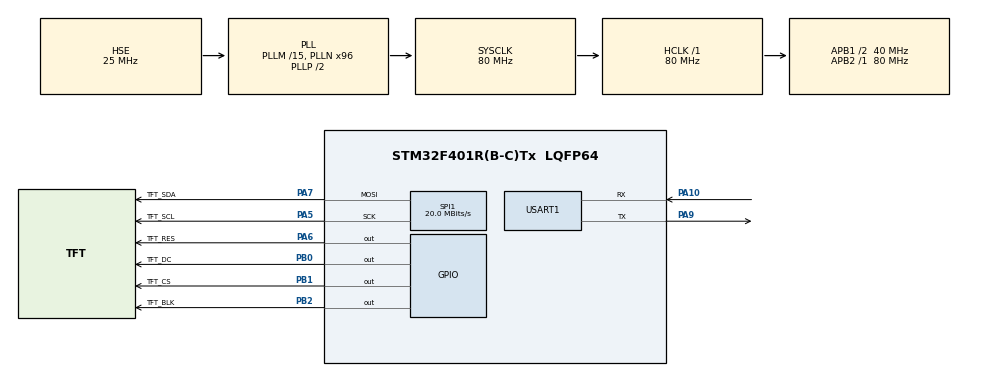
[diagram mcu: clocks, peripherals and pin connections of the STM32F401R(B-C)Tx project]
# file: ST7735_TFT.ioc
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Mcu.Family=STM32F4
Mcu.Name=STM32F401R(B-C)Tx
Mcu.Package=LQFP64
NVIC.PriorityGroup=NVIC_PRIORITYGROUP_4
PA10.Mode=Asynchronous
PA10.Signal=USART1_RX
PA13.Mode=Serial_Wire
PA13.Signal=SYS_JTMS-SWDIO
PA14.Mode=Serial_Wire
PA14.Signal=SYS_JTCK-SWCLK
PA5.GPIO_Label=TFT_SCL
PA5.Mode=TX_Only_Simplex_Unidirect_Master
PA5.Signal=SPI1_SCK
PA6.GPIO_Label=TFT_RES
PA6.Signal=GPIO_Output
PA7.GPIO_Label=TFT_SDA
PA7.Mode=TX_Only_Simplex_Unidirect_Master
PA7.Signal=SPI1_MOSI
PA9.Mode=Asynchronous
PA9.Signal=USART1_TX
PB0.GPIO_Label=TFT_DC
PB0.Signal=GPIO_Output
PB1.GPIO_Label=TFT_CS
PB1.Signal=GPIO_Output
PB2.GPIO_Label=TFT_BLK
PB2.Signal=GPIO_Output
PH0\ -\ OSC_IN.Mode=HSE-External-Oscillator
PH0\ -\ OSC_IN.Signal=RCC_OSC_IN
PH1\ -\ OSC_OUT.Mode=HSE-External-Oscillator
PH1\ -\ OSC_OUT.Signal=RCC_OSC_OUT
ProjectManager.HeapSize=0x200
ProjectManager.StackSize=0x400
ProjectManager.TargetToolchain=MDK-ARM V5.32
RCC.48MHZClocksFreq_Value=40000000
RCC.AHBFreq_Value=80000000
RCC.APB1CLKDivider=RCC_HCLK_DIV2
RCC.APB1Freq_Value=40000000
RCC.APB1TimFreq_Value=80000000
RCC.APB2Freq_Value=80000000
RCC.APB2TimFreq_Value=80000000
RCC.CortexFreq_Value=80000000
RCC.HCLKFreq_Value=80000000
RCC.HSE_VALUE=25000000
RCC.HSI_VALUE=16000000
RCC.LSE_VALUE=32768
RCC.PLLM=15
RCC.PLLN=96
RCC.PLLSourceVirtual=RCC_PLLSOURCE_HSE
RCC.SYSCLKFreq_VALUE=80000000
RCC.SYSCLKSource=RCC_SYSCLKSOURCE_PLLCLK
RCC.VCOOutputFreq_Value=160000000
SPI1.BaudRatePrescaler=SPI_BAUDRATEPRESCALER_4
SPI1.CalculateBaudRate=20.0 MBits/s
SPI1.Direction=SPI_DIRECTION_2LINES
SPI1.FirstBit=SPI_FIRSTBIT_MSB
SPI1.Mode=SPI_MODE_MASTER
SPI1.VirtualType=VM_MASTER
TIM11.Prescaler=80-1
USART1.VirtualMode=VM_ASYNC
VP_TIM11_VS_ClockSourceINT.Mode=Enable_Timer
board=custom

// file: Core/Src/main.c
/* USER CODE BEGIN Header */
/**
  ******************************************************************************
  * @file           : main.c
  * @brief          : Main program body
  ******************************************************************************
  * @attention
  *
  * Copyright (c) 2025 STMicroelectronics.
  * All rights reserved.
  *
  * This software is licensed under terms that can be found in the LICENSE file
  * in the root directory of this software component.
  * If no LICENSE file comes with this software, it is provided AS-IS.
  *
  ******************************************************************************
  */
/* USER CODE END Header */
#include "main.h"
#include "spi.h"
#include "tim.h"
#include "usart.h"
#include "gpio.h"

/* USER CODE BEGIN Includes */
#include "lcd.h"
/* USER CODE END Includes */

void SystemClock_Config(void);

int main(void)
{

  /* MCU Configuration--------------------------------------------------------*/

  /* Reset of all peripherals, Initializes the Flash interface and the Systick. */
  HAL_Init();

  /* Configure the system clock */
  SystemClock_Config();

  /* Initialize all configured peripherals */
  MX_GPIO_Init();
  MX_SPI1_Init();
  MX_USART1_UART_Init();
  MX_TIM11_Init();
  /* USER CODE BEGIN 2 */
	LCD_Init();
	HAL_TIM_Base_Start(&htim11);

	char ch[10]={0};
	uint32_t a=0,b=0;
  /* USER CODE END 2 */

  /* Infinite loop */
  /* USER CODE BEGIN WHILE */
  while (1)
  {
//		htim11.Instance->CNT = 0;
//		a = __HAL_TIM_GetCounter(&htim11);
//		b = __HAL_TIM_GetCounter(&htim11);
//		sprintf(ch,"%d->%d,",a,b);
//		HAL_UART_Transmit(&huart1,ch,sizeof(ch),100);
//		HAL_Delay(500);

//		// LCD 绘制函数 普通测试
//		LCD_FillScreen(LCD_BLACK);
//		LCD_DrawLine(0, 63, 0, 31, LCD_RED, LCD_Nor);
//		LCD_DrawRectangle(64, 127, 0, 31, LCD_RED, LCD_Nor);
//		LCD_DrawQuarterArc(64, 48, 10, Quarter1|Quarter2, LCD_RED, LCD_Nor);
//		LCD_DrawQuarterSector(64, 48, 10, Quarter3|Quarter4, LCD_RED, LCD_Nor);
//		LCD_RefreshScreen();
//		HAL_Delay(500);

//		// LCD 绘制函数 Xor测试
//		LCD_FillScreen(LCD_BLACK);
//		LCD_DrawQuarterArc(64, 48, 10, Quarter1|Quarter2, LCD_RED, LCD_Nor);
//		LCD_DrawQuarterSector(64, 48, 10, Quarter3|Quarter4, LCD_RED, LCD_Nor);
//		LCD_DrawLine(0, 63, 0, 31, LCD_RED, LCD_Xor);
//		LCD_DrawRectangle(48, 127, 0, 63, LCD_RED, LCD_Xor);
//		LCD_RefreshScreen();
//		HAL_Delay(500);

    /* USER CODE END WHILE */

  }
}

void SystemClock_Config(void)
{
  RCC_OscInitTypeDef RCC_OscInitStruct = {0};
  RCC_ClkInitTypeDef RCC_ClkInitStruct = {0};

  /** Configure the main internal regulator output voltage
  */
  __HAL_RCC_PWR_CLK_ENABLE();
  __HAL_PWR_VOLTAGESCALING_CONFIG(PWR_REGULATOR_VOLTAGE_SCALE2);

  /** Initializes the RCC Oscillators according to the specified parameters
  * in the RCC_OscInitTypeDef structure.
  */
  RCC_OscInitStruct.OscillatorType = RCC_OSCILLATORTYPE_HSE;
  RCC_OscInitStruct.HSEState = RCC_HSE_ON;
  RCC_OscInitStruct.PLL.PLLState = RCC_PLL_ON;
  RCC_OscInitStruct.PLL.PLLSource = RCC_PLLSOURCE_HSE;
  RCC_OscInitStruct.PLL.PLLM = 15;
  RCC_OscInitStruct.PLL.PLLN = 96;
  RCC_OscInitStruct.PLL.PLLP = RCC_PLLP_DIV2;
  RCC_OscInitStruct.PLL.PLLQ = 4;
  if (HAL_RCC_OscConfig(&RCC_OscInitStruct) != HAL_OK)
  {
    Error_Handler();
  }

  /** Initializes the CPU, AHB and APB buses clocks
  */
  RCC_ClkInitStruct.ClockType = RCC_CLOCKTYPE_HCLK|RCC_CLOCKTYPE_SYSCLK
                              |RCC_CLOCKTYPE_PCLK1|RCC_CLOCKTYPE_PCLK2;
  RCC_ClkInitStruct.SYSCLKSource = RCC_SYSCLKSOURCE_PLLCLK;
  RCC_ClkInitStruct.AHBCLKDivider = RCC_SYSCLK_DIV1;
  RCC_ClkInitStruct.APB1CLKDivider = RCC_HCLK_DIV2;
  RCC_ClkInitStruct.APB2CLKDivider = RCC_HCLK_DIV1;

  if (HAL_RCC_ClockConfig(&RCC_ClkInitStruct, FLASH_LATENCY_2) != HAL_OK)
  {
    Error_Handler();
  }
}

void Error_Handler(void)
{
  __disable_irq();
  while (1)
  {
  }
}
